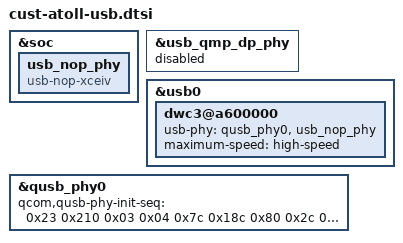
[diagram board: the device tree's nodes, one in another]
&soc {
	usb_nop_phy: usb_nop_phy{ 
		status = "okay";
		compatible = "usb-nop-xceiv"; 
	}; 
};

&usb_qmp_dp_phy {
	status = "disabled";
};

&usb0 {
	dwc3@a600000 {
		usb-phy = <&qusb_phy0>, <&usb_nop_phy>;
		maximum-speed = "high-speed";
	};
};

&qusb_phy0 {
		qcom,qusb-phy-init-seq =
			/* <value reg_offset> */
			<0x23 0x210 /* PWR_CTRL1 */
			 0x03 0x04  /* PLL_ANALOG_CONTROLS_TWO */
			 0x7c 0x18c /* PLL_CLOCK_INVERTERS */
			 0x80 0x2c  /* PLL_CMODE */
			 0x0a 0x184 /* PLL_LOCK_DELAY */
			 0x19 0xb4  /* PLL_DIGITAL_TIMERS_TWO */
			 0x40 0x194 /* PLL_BIAS_CONTROL_1 */
			 0x16 0x198 /* PLL_BIAS_CONTROL_2 */
			 0x21 0x214 /* PWR_CTRL2 */
			 0x08 0x220 /* IMP_CTRL1 */
			 0x58 0x224 /* IMP_CTRL2 */
			 0x67 0x240 /* TUNE1 */
			 0x28 0x244 /* TUNE2 */
			 0xca 0x248 /* TUNE3 */
			 0x04 0x24c /* TUNE4 */
			 0x03 0x250 /* TUNE5 */
			 0x30 0x23c /* CHG_CTRL2 */
			 0x22 0x210>; /* PWR_CTRL1 */
};
